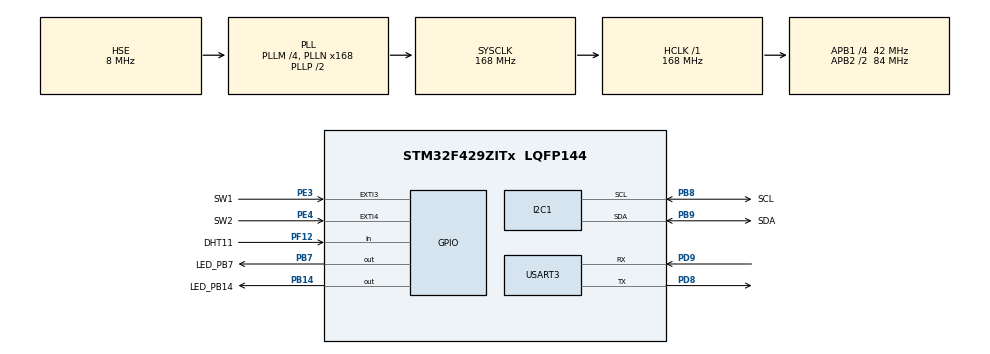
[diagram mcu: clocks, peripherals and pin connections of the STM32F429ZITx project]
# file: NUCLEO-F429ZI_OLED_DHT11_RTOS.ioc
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FREERTOS.Tasks01=defaultTask,24,128,StartDefaultTask,Default,NULL,Dynamic,NULL,NULL
I2C1.I2C_Mode=I2C_Fast
Mcu.Family=STM32F4
Mcu.Name=STM32F429ZITx
Mcu.Package=LQFP144
NVIC.EXTI3_IRQn=true\:5\:0\:false\:false\:true\:true\:true\:true\:true
NVIC.EXTI4_IRQn=true\:5\:0\:false\:false\:true\:true\:true\:true\:true
NVIC.PriorityGroup=NVIC_PRIORITYGROUP_4
NVIC.TIM1_UP_TIM10_IRQn=true\:15\:0\:false\:false\:true\:false\:false\:true\:true
NVIC.TimeBase=TIM1_UP_TIM10_IRQn
NVIC.TimeBaseIP=TIM1
PA13.GPIO_Label=TMS
PA13.Mode=Serial_Wire
PA13.Signal=SYS_JTMS-SWDIO
PA14.GPIO_Label=TCK
PA14.Mode=Serial_Wire
PA14.Signal=SYS_JTCK-SWCLK
PB14.GPIO_Label=LED_PB14
PB14.Signal=GPIO_Output
PB7.GPIO_Label=LED_PB7
PB7.Signal=GPIO_Output
PB8.GPIO_Label=SCL
PB8.Mode=I2C
PB8.Signal=I2C1_SCL
PB9.GPIO_Label=SDA
PB9.Mode=I2C
PB9.Signal=I2C1_SDA
PD8.Mode=Asynchronous
PD8.Signal=USART3_TX
PD9.Mode=Asynchronous
PD9.Signal=USART3_RX
PE3.GPIO_Label=SW1
PE3.Signal=GPXTI3
PE4.GPIO_Label=SW2
PE4.Signal=GPXTI4
PF12.GPIO_Label=DHT11
PF12.Signal=GPIO_Input
PH0/OSC_IN.Mode=HSE-External-Oscillator
PH0/OSC_IN.Signal=RCC_OSC_IN
PH1/OSC_OUT.Mode=HSE-External-Oscillator
PH1/OSC_OUT.Signal=RCC_OSC_OUT
ProjectManager.HeapSize=0x200
ProjectManager.StackSize=0x400
ProjectManager.TargetToolchain=MDK-ARM V5.32
RCC.48MHZClocksFreq_Value=84000000
RCC.AHBFreq_Value=168000000
RCC.APB1CLKDivider=RCC_HCLK_DIV4
RCC.APB1Freq_Value=42000000
RCC.APB1TimFreq_Value=84000000
RCC.APB2CLKDivider=RCC_HCLK_DIV2
RCC.APB2Freq_Value=84000000
RCC.APB2TimFreq_Value=168000000
RCC.CortexFreq_Value=168000000
RCC.HCLKFreq_Value=168000000
RCC.HSE_VALUE=8000000
RCC.HSI_VALUE=16000000
RCC.LSE_VALUE=32768
RCC.PLLM=4
RCC.PLLMUL=RCC_PLL_MUL9
RCC.PLLN=168
RCC.PLLSourceVirtual=RCC_PLLSOURCE_HSE
RCC.PRESCALERUSB=RCC_USBCLKSOURCE_PLL_DIV1_5
RCC.SYSCLKFreq_VALUE=168000000
RCC.SYSCLKSource=RCC_SYSCLKSOURCE_PLLCLK
RCC.SYSCLKSourceVirtual=RCC_SYSCLKSOURCE_PLLCLK
RCC.USBFreq_Value=48000000
RCC.VCOOutputFreq_Value=336000000
TIM2.Prescaler=83
USART3.VirtualMode=VM_ASYNC
VP_FREERTOS_VS_CMSIS_V2.Mode=CMSIS_V2
VP_SYS_VS_tim1.Mode=TIM1
VP_TIM2_VS_ClockSourceINT.Mode=Internal
board=NUCLEO-F429ZI

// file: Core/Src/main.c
/* USER CODE BEGIN Header */
/**
  ******************************************************************************
  * @file           : main.c
  * @brief          : Main program body
  ******************************************************************************
  * @attention
  *
  * Copyright (c) 2025 STMicroelectronics.
  * All rights reserved.
  *
  * This software is licensed under terms that can be found in the LICENSE file
  * in the root directory of this software component.
  * If no LICENSE file comes with this software, it is provided AS-IS.
  *
  ******************************************************************************
  */
/* USER CODE END Header */
#include "main.h"
#include "cmsis_os.h"
#include "i2c.h"
#include "tim.h"
#include "usart.h"
#include "gpio.h"

/* USER CODE BEGIN Includes */
#include "dht11.h"
#include "oled_driver.h"
#include "oled_rtos_task.h"
#include "dht11_rtos_task.h"
/* USER CODE END Includes */

void SystemClock_Config(void);
void MX_FREERTOS_Init(void);

int main(void)
{

  /* MCU Configuration--------------------------------------------------------*/

  /* Reset of all peripherals, Initializes the Flash interface and the Systick. */
  HAL_Init();

  /* Configure the system clock */
  SystemClock_Config();

  /* Initialize all configured peripherals */
  MX_GPIO_Init();
  MX_I2C1_Init();
  MX_TIM2_Init();
  MX_USART3_UART_Init();

  /* Init scheduler */
  osKernelInitialize();

  /* Call init function for freertos objects (in cmsis_os2.c) */
  //MX_FREERTOS_Init();
  OLED_Task_Init();
  DHT11_Task_Init();

  /* Start scheduler */
  osKernelStart();

  /* We should never get here as control is now taken by the scheduler */

  /* Infinite loop */
  while (1)
  {

  }
}

void SystemClock_Config(void)
{
  RCC_OscInitTypeDef RCC_OscInitStruct = {0};
  RCC_ClkInitTypeDef RCC_ClkInitStruct = {0};

  /** Configure the main internal regulator output voltage
  */
  __HAL_RCC_PWR_CLK_ENABLE();
  __HAL_PWR_VOLTAGESCALING_CONFIG(PWR_REGULATOR_VOLTAGE_SCALE1);

  /** Initializes the RCC Oscillators according to the specified parameters
  * in the RCC_OscInitTypeDef structure.
  */
  RCC_OscInitStruct.OscillatorType = RCC_OSCILLATORTYPE_HSE;
  RCC_OscInitStruct.HSEState = RCC_HSE_ON;
  RCC_OscInitStruct.PLL.PLLState = RCC_PLL_ON;
  RCC_OscInitStruct.PLL.PLLSource = RCC_PLLSOURCE_HSE;
  RCC_OscInitStruct.PLL.PLLM = 4;
  RCC_OscInitStruct.PLL.PLLN = 168;
  RCC_OscInitStruct.PLL.PLLP = RCC_PLLP_DIV2;
  RCC_OscInitStruct.PLL.PLLQ = 4;
  if (HAL_RCC_OscConfig(&RCC_OscInitStruct) != HAL_OK)
  {
    Error_Handler();
  }

  /** Initializes the CPU, AHB and APB buses clocks
  */
  RCC_ClkInitStruct.ClockType = RCC_CLOCKTYPE_HCLK|RCC_CLOCKTYPE_SYSCLK
                              |RCC_CLOCKTYPE_PCLK1|RCC_CLOCKTYPE_PCLK2;
  RCC_ClkInitStruct.SYSCLKSource = RCC_SYSCLKSOURCE_PLLCLK;
  RCC_ClkInitStruct.AHBCLKDivider = RCC_SYSCLK_DIV1;
  RCC_ClkInitStruct.APB1CLKDivider = RCC_HCLK_DIV4;
  RCC_ClkInitStruct.APB2CLKDivider = RCC_HCLK_DIV2;

  if (HAL_RCC_ClockConfig(&RCC_ClkInitStruct, FLASH_LATENCY_5) != HAL_OK)
  {
    Error_Handler();
  }
}

void HAL_TIM_PeriodElapsedCallback(TIM_HandleTypeDef *htim)
{
  if (htim->Instance == TIM1)
  {
    HAL_IncTick();
  }
}

void Error_Handler(void)
{
  __disable_irq();
  while (1)
  {
  }
}

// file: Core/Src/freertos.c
/* USER CODE BEGIN Header */
/**
  ******************************************************************************
  * File Name          : freertos.c
  * Description        : Code for freertos applications
  ******************************************************************************
  * @attention
  *
  * Copyright (c) 2025 STMicroelectronics.
  * All rights reserved.
  *
  * This software is licensed under terms that can be found in the LICENSE file
  * in the root directory of this software component.
  * If no LICENSE file comes with this software, it is provided AS-IS.
  *
  ******************************************************************************
  */
/* USER CODE END Header */

#include "FreeRTOS.h"
#include "task.h"
#include "main.h"
#include "cmsis_os.h"

/* Definitions for defaultTask */
osThreadId_t defaultTaskHandle;
const osThreadAttr_t defaultTask_attributes = {
  .name = "defaultTask",
  .stack_size = 128 * 4,
  .priority = (osPriority_t) osPriorityNormal,
};

void StartDefaultTask(void *argument);

void MX_FREERTOS_Init(void); /* (MISRA C 2004 rule 8.1) */

void MX_FREERTOS_Init(void) {

  /* Create the thread(s) */
  /* creation of defaultTask */
  //defaultTaskHandle = osThreadNew(StartDefaultTask, NULL, &defaultTask_attributes);

}

void StartDefaultTask(void *argument)
{
  for(;;)
  {
    osDelay(1);
  }
}
